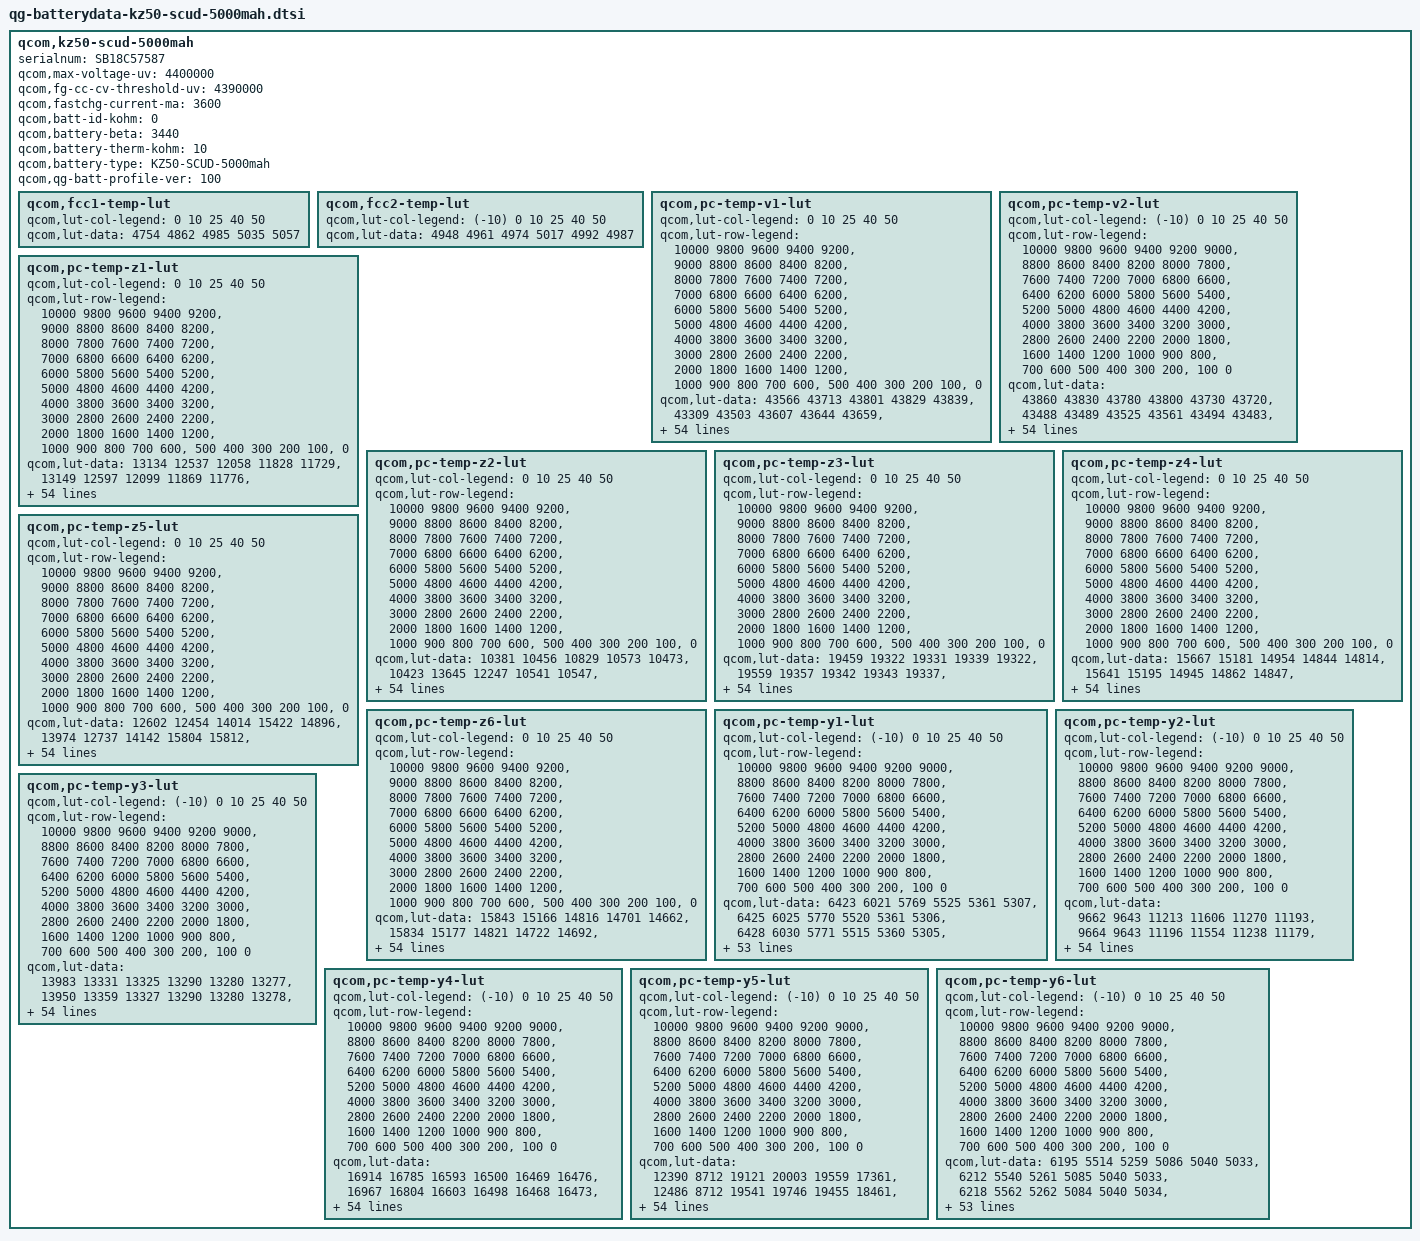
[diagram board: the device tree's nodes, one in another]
qcom,kz50-scud-5000mah {
    /* 4166775_Lenovo_Sofia_SCUD_5000mAH_PMI632_averaged_MasterSlave_Aug21th2019 */
    serialnum = "SB18C57587";
    qcom,max-voltage-uv = <4400000>;
    qcom,fg-cc-cv-threshold-uv = <4390000>;
    qcom,fastchg-current-ma = <3600>;
    qcom,batt-id-kohm = <0>;
    qcom,battery-beta = <3440>;
    qcom,battery-therm-kohm = <10>;
    qcom,battery-type = "KZ50-SCUD-5000mah";
    qcom,qg-batt-profile-ver = <100>;

	qcom,fcc1-temp-lut {
		qcom,lut-col-legend = <0 10 25 40 50>;
		qcom,lut-data = <4754 4862 4985 5035 5057>;
	};

	qcom,fcc2-temp-lut {
		qcom,lut-col-legend = <(-10) 0 10 25 40 50>;
		qcom,lut-data = <4948 4961 4974 5017 4992 4987>;
	};

	qcom,pc-temp-v1-lut {
		qcom,lut-col-legend = <0 10 25 40 50>;
		qcom,lut-row-legend = <10000 9800 9600 9400 9200>,
			<9000 8800 8600 8400 8200>,
			<8000 7800 7600 7400 7200>,
			<7000 6800 6600 6400 6200>,
			<6000 5800 5600 5400 5200>,
			<5000 4800 4600 4400 4200>,
			<4000 3800 3600 3400 3200>,
			<3000 2800 2600 2400 2200>,
			<2000 1800 1600 1400 1200>,
			<1000 900 800 700 600>,
			<500 400 300 200 100>,
			<0>;
		qcom,lut-data = <43566 43713 43801 43829 43839>,
			<43309 43503 43607 43644 43659>,
			<43060 43264 43399 43435 43457>,
			<42821 43005 43174 43218 43244>,
			<42591 42759 42929 42996 43021>,
			<42370 42527 42684 42768 42789>,
			<42156 42302 42446 42533 42557>,
			<41949 42083 42211 42292 42323>,
			<41748 41870 41983 42056 42091>,
			<41549 41661 41760 41827 41863>,
			<41356 41454 41543 41603 41637>,
			<41168 41254 41330 41384 41415>,
			<40995 41070 41122 41167 41194>,
			<40803 40905 40929 40960 40981>,
			<40532 40718 40750 40761 40773>,
			<40198 40439 40556 40568 40572>,
			<39956 40126 40322 40375 40381>,
			<39817 39929 40085 40183 40200>,
			<39706 39816 39908 40000 40021>,
			<39591 39706 39776 39833 39849>,
			<39476 39556 39616 39658 39672>,
			<39361 39381 39341 39422 39449>,
			<39241 39194 39046 39144 39182>,
			<39119 38967 38886 38953 38982>,
			<38991 38765 38789 38837 38862>,
			<38848 38655 38702 38740 38761>,
			<38713 38582 38611 38639 38649>,
			<38607 38517 38526 38543 38535>,
			<38517 38457 38448 38450 38434>,
			<38447 38402 38374 38357 38345>,
			<38398 38352 38306 38272 38266>,
			<38359 38305 38242 38201 38195>,
			<38325 38262 38184 38137 38132>,
			<38296 38224 38131 38076 38067>,
			<38268 38190 38084 38020 38001>,
			<38234 38152 38038 37965 37934>,
			<38195 38114 37993 37912 37871>,
			<38147 38069 37945 37859 37809>,
			<38078 37998 37878 37788 37730>,
			<37993 37900 37783 37689 37625>,
			<37898 37791 37675 37576 37508>,
			<37785 37665 37557 37459 37383>,
			<37650 37526 37424 37329 37249>,
			<37486 37368 37271 37178 37096>,
			<37345 37241 37144 37055 36985>,
			<37248 37162 37071 36984 36923>,
			<37212 37144 37045 36957 36896>,
			<37185 37120 37033 36941 36879>,
			<37151 37091 37004 36909 36841>,
			<37049 36990 36890 36777 36673>,
			<36737 36667 36552 36422 36324>,
			<36274 36205 36091 35958 35860>,
			<35685 35614 35498 35361 35261>,
			<34884 34808 34692 34547 34441>,
			<33604 33529 33413 33255 33140>,
			<30000 30000 30000 30000 30000>;
	};

	qcom,pc-temp-v2-lut {
		qcom,lut-col-legend = <(-10) 0 10 25 40 50>;
		qcom,lut-row-legend = <10000 9800 9600 9400 9200 9000>,
			<8800 8600 8400 8200 8000 7800>,
			<7600 7400 7200 7000 6800 6600>,
			<6400 6200 6000 5800 5600 5400>,
			<5200 5000 4800 4600 4400 4200>,
			<4000 3800 3600 3400 3200 3000>,
			<2800 2600 2400 2200 2000 1800>,
			<1600 1400 1200 1000 900 800>,
			<700 600 500 400 300 200>,
			<100 0>;
		qcom,lut-data = <43860 43830 43780 43800 43730 43720>,
			<43488 43489 43525 43561 43494 43483>,
			<43138 43181 43274 43324 43260 43248>,
			<42814 42912 43027 43086 43025 43014>,
			<42512 42679 42784 42849 42791 42783>,
			<42232 42450 42543 42612 42557 42551>,
			<41966 42209 42304 42377 42323 42318>,
			<41720 41964 42069 42143 42091 42085>,
			<41506 41706 41843 41914 41862 41856>,
			<41304 41415 41626 41688 41636 41630>,
			<41156 41187 41415 41464 41412 41406>,
			<41088 41076 41212 41241 41192 41187>,
			<41041 40994 41014 41023 40975 40970>,
			<40888 40837 40817 40831 40769 40763>,
			<40268 40508 40627 40663 40570 40561>,
			<39669 40156 40412 40475 40377 40366>,
			<39455 39880 40113 40219 40185 40177>,
			<39316 39628 39777 39948 39996 39995>,
			<39160 39415 39541 39742 39808 39811>,
			<38975 39238 39381 39578 39624 39630>,
			<38795 39069 39231 39406 39429 39439>,
			<38634 38879 39060 39188 39199 39209>,
			<38486 38685 38889 38969 38963 38970>,
			<38374 38523 38738 38801 38789 38791>,
			<38292 38383 38605 38665 38655 38656>,
			<38224 38268 38484 38544 38537 38537>,
			<38164 38181 38374 38435 38426 38425>,
			<38111 38112 38273 38336 38325 38322>,
			<38061 38054 38181 38243 38234 38230>,
			<38016 38005 38093 38156 38151 38146>,
			<37972 37962 38014 38077 38076 38069>,
			<37926 37919 37937 38005 38007 38000>,
			<37879 37879 37867 37937 37943 37935>,
			<37829 37838 37814 37869 37870 37858>,
			<37776 37796 37778 37802 37789 37767>,
			<37720 37750 37740 37733 37701 37668>,
			<37658 37697 37686 37660 37604 37559>,
			<37593 37636 37621 37584 37501 37446>,
			<37522 37566 37553 37509 37412 37350>,
			<37442 37488 37486 37436 37338 37272>,
			<37357 37400 37410 37352 37257 37190>,
			<37275 37301 37308 37246 37148 37083>,
			<37194 37191 37187 37129 37030 36967>,
			<37116 37085 37076 36998 36917 36856>,
			<37038 36983 36974 36919 36841 36784>,
			<36944 36886 36907 36880 36809 36752>,
			<36891 36832 36888 36864 36794 36737>,
			<36822 36773 36853 36837 36770 36711>,
			<36731 36691 36777 36775 36712 36641>,
			<36593 36535 36601 36583 36478 36390>,
			<36326 36250 36232 36165 36061 35968>,
			<35912 35805 35688 35620 35522 35420>,
			<35311 35170 34983 34901 34805 34704>,
			<34445 34245 33955 33853 33785 33694>,
			<32973 32770 32489 32484 32409 32235>,
			<29704 27720 27389 27346 27270 27172>;
	};

	qcom,pc-temp-z1-lut {
		qcom,lut-col-legend = <0 10 25 40 50>;
		qcom,lut-row-legend = <10000 9800 9600 9400 9200>,
			<9000 8800 8600 8400 8200>,
			<8000 7800 7600 7400 7200>,
			<7000 6800 6600 6400 6200>,
			<6000 5800 5600 5400 5200>,
			<5000 4800 4600 4400 4200>,
			<4000 3800 3600 3400 3200>,
			<3000 2800 2600 2400 2200>,
			<2000 1800 1600 1400 1200>,
			<1000 900 800 700 600>,
			<500 400 300 200 100>,
			<0>;
		qcom,lut-data = <13134 12537 12058 11828 11729>,
			<13149 12597 12099 11869 11776>,
			<13159 12593 12124 11881 11788>,
			<13160 12579 12126 11884 11794>,
			<13157 12572 12123 11883 11797>,
			<13156 12570 12120 11882 11799>,
			<13157 12570 12117 11883 11802>,
			<13163 12573 12115 11884 11806>,
			<13166 12584 12113 11886 11810>,
			<13150 12589 12111 11889 11817>,
			<13126 12585 12111 11892 11824>,
			<13116 12579 12119 11898 11830>,
			<13107 12573 12129 11906 11836>,
			<13100 12561 12127 11908 11839>,
			<13087 12548 12114 11906 11840>,
			<13061 12534 12106 11904 11841>,
			<13051 12521 12104 11904 11843>,
			<13043 12519 12103 11905 11845>,
			<13032 12527 12104 11906 11847>,
			<13030 12536 12112 11907 11847>,
			<13037 12543 12118 11909 11848>,
			<13043 12548 12119 11910 11849>,
			<13045 12552 12119 11910 11850>,
			<13048 12554 12121 11911 11852>,
			<13051 12557 12124 11914 11853>,
			<13055 12559 12128 11917 11855>,
			<13059 12562 12133 11920 11857>,
			<13061 12565 12139 11923 11860>,
			<13063 12572 12141 11926 11863>,
			<13066 12579 12144 11930 11866>,
			<13073 12582 12146 11934 11869>,
			<13084 12583 12150 11938 11873>,
			<13093 12585 12155 11942 11877>,
			<13106 12593 12158 11946 11881>,
			<13116 12604 12162 11951 11885>,
			<13117 12609 12165 11955 11890>,
			<13111 12611 12171 11958 11894>,
			<13110 12613 12178 11962 11897>,
			<13118 12616 12184 11966 11900>,
			<13128 12622 12189 11971 11904>,
			<13138 12629 12193 11975 11908>,
			<13150 12642 12195 11979 11910>,
			<13161 12651 12198 11983 11913>,
			<13171 12657 12203 11987 11916>,
			<13181 12663 12212 11993 11920>,
			<13199 12675 12222 11998 11921>,
			<13179 12670 12215 11997 11921>,
			<13193 12656 12215 12000 11923>,
			<13207 12665 12220 12003 11928>,
			<13199 12674 12223 12010 11933>,
			<13210 12684 12235 12015 11938>,
			<13241 12693 12250 12024 11947>,
			<13233 12720 12254 12037 11958>,
			<13266 12761 12278 12054 11974>,
			<13266 12761 12278 12054 11974>,
			<13266 12761 12278 12054 11974>;
	};

	qcom,pc-temp-z2-lut {
		qcom,lut-col-legend = <0 10 25 40 50>;
		qcom,lut-row-legend = <10000 9800 9600 9400 9200>,
			<9000 8800 8600 8400 8200>,
			<8000 7800 7600 7400 7200>,
			<7000 6800 6600 6400 6200>,
			<6000 5800 5600 5400 5200>,
			<5000 4800 4600 4400 4200>,
			<4000 3800 3600 3400 3200>,
			<3000 2800 2600 2400 2200>,
			<2000 1800 1600 1400 1200>,
			<1000 900 800 700 600>,
			<500 400 300 200 100>,
			<0>;
		qcom,lut-data = <10381 10456 10829 10573 10473>,
			<10423 13645 12247 10541 10547>,
			<10449 13062 12988 10598 10607>,
			<10454 11329 12852 10710 10637>,
			<10440 10617 12007 11466 10614>,
			<10423 10583 11396 12318 10568>,
			<10416 10563 11038 12114 10549>,
			<10410 10540 10722 11097 10542>,
			<10407 10519 10652 10590 10534>,
			<10458 10502 10627 10556 10510>,
			<10550 10484 10613 10537 10481>,
			<10566 10471 10605 10524 10479>,
			<10468 10509 10599 10513 10497>,
			<10358 10709 10690 10541 10511>,
			<10304 10845 11102 11324 10517>,
			<10255 10734 11454 12241 10520>,
			<10237 10540 11657 12497 10501>,
			<10239 10491 11793 12632 10423>,
			<10243 10506 11659 12608 10382>,
			<10249 10529 11014 11565 10476>,
			<10265 10558 10643 10519 10598>,
			<10281 10593 10716 10517 10620>,
			<10292 10604 10817 10665 10624>,
			<10302 10599 10807 10711 10619>,
			<10315 10593 10695 10604 10592>,
			<10333 10596 10630 10504 10564>,
			<10351 10607 10662 10535 10672>,
			<10366 10612 10714 10625 10997>,
			<10379 10612 10734 10685 11123>,
			<10389 10611 10744 10789 10951>,
			<10394 10611 10751 10870 10725>,
			<10398 10616 10761 10829 10599>,
			<10403 10621 10769 10723 10502>,
			<10409 10626 10770 10653 10432>,
			<10416 10635 10764 10602 10371>,
			<10428 10642 10760 10575 10337>,
			<10444 10649 10781 10581 10366>,
			<10462 10658 10820 10601 10450>,
			<10485 10676 10849 10628 10527>,
			<10504 10698 10875 10705 10598>,
			<10419 10706 10895 10782 10668>,
			<10012 10700 10913 10829 10748>,
			<9901 10697 10923 10856 10826>,
			<10024 10709 10912 10815 10876>,
			<10390 10849 10939 10761 10791>,
			<10531 10886 10934 10669 10553>,
			<10601 10881 10906 10664 10556>,
			<10581 10960 10825 10679 10585>,
			<10841 11121 10872 10754 10677>,
			<10695 11097 11005 10769 10647>,
			<10218 10967 10981 10610 10408>,
			<9983 10854 10904 10464 10285>,
			<9796 10723 10810 10382 10224>,
			<9654 10517 10710 10334 10158>,
			<9654 10517 10710 10334 10158>,
			<9654 10517 10710 10334 10158>;
	};

	qcom,pc-temp-z3-lut {
		qcom,lut-col-legend = <0 10 25 40 50>;
		qcom,lut-row-legend = <10000 9800 9600 9400 9200>,
			<9000 8800 8600 8400 8200>,
			<8000 7800 7600 7400 7200>,
			<7000 6800 6600 6400 6200>,
			<6000 5800 5600 5400 5200>,
			<5000 4800 4600 4400 4200>,
			<4000 3800 3600 3400 3200>,
			<3000 2800 2600 2400 2200>,
			<2000 1800 1600 1400 1200>,
			<1000 900 800 700 600>,
			<500 400 300 200 100>,
			<0>;
		qcom,lut-data = <19459 19322 19331 19339 19322>,
			<19559 19357 19342 19343 19337>,
			<19634 19416 19358 19363 19356>,
			<19664 19498 19379 19381 19374>,
			<19674 19531 19410 19395 19383>,
			<19680 19535 19427 19405 19390>,
			<19680 19537 19431 19407 19396>,
			<19676 19538 19434 19407 19401>,
			<19674 19538 19434 19407 19403>,
			<19680 19538 19433 19407 19402>,
			<19689 19536 19431 19405 19401>,
			<19687 19532 19429 19401 19399>,
			<19656 19531 19427 19393 19395>,
			<19628 19530 19427 19390 19391>,
			<19644 19529 19432 19399 19387>,
			<19690 19525 19435 19408 19383>,
			<19710 19518 19436 19407 19377>,
			<19691 19508 19437 19401 19368>,
			<19661 19491 19433 19393 19362>,
			<19643 19479 19412 19375 19360>,
			<19629 19483 19400 19360 19359>,
			<19622 19493 19404 19360 19357>,
			<19622 19498 19410 19364 19354>,
			<19622 19499 19408 19364 19350>,
			<19624 19500 19394 19350 19339>,
			<19633 19499 19386 19338 19329>,
			<19642 19498 19385 19339 19345>,
			<19642 19496 19384 19347 19395>,
			<19639 19495 19385 19358 19415>,
			<19635 19493 19390 19381 19411>,
			<19629 19492 19395 19398 19403>,
			<19621 19492 19402 19397 19395>,
			<19612 19491 19407 19392 19384>,
			<19601 19490 19408 19387 19374>,
			<19590 19488 19407 19379 19365>,
			<19581 19485 19404 19371 19357>,
			<19573 19482 19400 19364 19352>,
			<19566 19478 19395 19358 19347>,
			<19560 19474 19392 19355 19345>,
			<19553 19470 19389 19353 19344>,
			<19504 19467 19387 19352 19344>,
			<19323 19463 19386 19354 19350>,
			<19266 19459 19384 19357 19360>,
			<19264 19453 19380 19356 19362>,
			<19261 19427 19372 19352 19358>,
			<19260 19403 19359 19339 19338>,
			<19260 19338 19361 19338 19335>,
			<19260 19322 19341 19330 19326>,
			<19259 19305 19340 19324 19318>,
			<19259 19316 19328 19331 19335>,
			<19261 19320 19352 19356 19353>,
			<19263 19317 19361 19359 19355>,
			<19265 19314 19366 19360 19355>,
			<19268 19311 19338 19352 19351>,
			<19268 19311 19338 19352 19351>,
			<19268 19311 19338 19352 19351>;
	};

	qcom,pc-temp-z4-lut {
		qcom,lut-col-legend = <0 10 25 40 50>;
		qcom,lut-row-legend = <10000 9800 9600 9400 9200>,
			<9000 8800 8600 8400 8200>,
			<8000 7800 7600 7400 7200>,
			<7000 6800 6600 6400 6200>,
			<6000 5800 5600 5400 5200>,
			<5000 4800 4600 4400 4200>,
			<4000 3800 3600 3400 3200>,
			<3000 2800 2600 2400 2200>,
			<2000 1800 1600 1400 1200>,
			<1000 900 800 700 600>,
			<500 400 300 200 100>,
			<0>;
		qcom,lut-data = <15667 15181 14954 14844 14814>,
			<15641 15195 14945 14862 14847>,
			<15591 15169 14929 14861 14844>,
			<15525 15092 14906 14858 14841>,
			<15414 15022 14869 14821 14828>,
			<15294 14962 14837 14776 14807>,
			<15207 14908 14815 14765 14788>,
			<15136 14864 14795 14761 14771>,
			<15073 14826 14776 14756 14755>,
			<15010 14800 14757 14742 14740>,
			<14953 14785 14742 14726 14727>,
			<14920 14772 14732 14718 14716>,
			<14900 14747 14723 14712 14708>,
			<14884 14698 14703 14702 14701>,
			<14872 14669 14664 14671 14697>,
			<14862 14694 14644 14644 14695>,
			<14849 14737 14648 14642 14692>,
			<14826 14745 14654 14642 14690>,
			<14799 14721 14659 14643 14688>,
			<14779 14701 14664 14657 14689>,
			<14763 14701 14672 14682 14690>,
			<14750 14705 14736 14729 14713>,
			<14739 14715 14818 14799 14789>,
			<14731 14768 14830 14824 14824>,
			<14729 14821 14828 14825 14824>,
			<14737 14822 14823 14825 14822>,
			<14749 14806 14813 14817 14798>,
			<14756 14790 14797 14794 14732>,
			<14763 14776 14781 14767 14700>,
			<14766 14762 14763 14733 14695>,
			<14762 14749 14746 14705 14692>,
			<14753 14737 14730 14695 14689>,
			<14746 14727 14716 14689 14685>,
			<14739 14717 14707 14688 14684>,
			<14732 14708 14701 14688 14685>,
			<14726 14701 14698 14689 14686>,
			<14720 14694 14696 14689 14685>,
			<14715 14690 14694 14688 14685>,
			<14710 14690 14695 14689 14686>,
			<14706 14691 14700 14700 14699>,
			<14748 14691 14703 14708 14709>,
			<14942 14688 14699 14703 14702>,
			<15000 14684 14692 14695 14692>,
			<14986 14680 14690 14695 14692>,
			<14914 14664 14674 14683 14681>,
			<14903 14667 14657 14666 14665>,
			<14899 14731 14646 14656 14657>,
			<14894 14743 14651 14645 14645>,
			<14884 14755 14641 14632 14630>,
			<14876 14738 14657 14633 14635>,
			<14885 14748 14658 14649 14658>,
			<14899 14759 14653 14654 14665>,
			<14911 14770 14653 14658 14671>,
			<14927 14782 14688 14671 14678>,
			<14927 14782 14688 14671 14678>,
			<14927 14782 14688 14671 14678>;
	};

	qcom,pc-temp-z5-lut {
		qcom,lut-col-legend = <0 10 25 40 50>;
		qcom,lut-row-legend = <10000 9800 9600 9400 9200>,
			<9000 8800 8600 8400 8200>,
			<8000 7800 7600 7400 7200>,
			<7000 6800 6600 6400 6200>,
			<6000 5800 5600 5400 5200>,
			<5000 4800 4600 4400 4200>,
			<4000 3800 3600 3400 3200>,
			<3000 2800 2600 2400 2200>,
			<2000 1800 1600 1400 1200>,
			<1000 900 800 700 600>,
			<500 400 300 200 100>,
			<0>;
		qcom,lut-data = <12602 12454 14014 15422 14896>,
			<13974 12737 14142 15804 15812>,
			<15064 14290 14472 17410 17523>,
			<15719 17127 15265 18726 19191>,
			<16095 18981 17207 19362 20117>,
			<16377 19795 18914 19935 20889>,
			<16661 20500 20106 20847 21904>,
			<16977 21542 21183 22100 23253>,
			<17384 22853 22060 23219 24518>,
			<18235 24128 22847 24287 25483>,
			<19173 25214 23680 25043 26381>,
			<19271 26331 24495 25153 27434>,
			<18342 27957 25515 25167 28723>,
			<17522 30493 27949 25533 29796>,
			<19366 31934 33103 32966 30652>,
			<24263 31411 35835 40853 31262>,
			<26510 30258 35687 41396 30995>,
			<25232 29195 35417 41187 29574>,
			<23579 27999 35470 40532 28838>,
			<23351 27248 35705 34753 30328>,
			<23841 33976 36145 29058 32198>,
			<24677 49538 40084 28701 31609>,
			<26582 55290 45187 28814 28248>,
			<30279 54201 43571 28386 24568>,
			<35260 52229 32694 23089 20121>,
			<45263 49073 25103 18040 16691>,
			<54223 43871 23338 17670 19365>,
			<55479 40253 22341 17754 28232>,
			<55044 38356 22362 18456 32395>,
			<54120 37158 23228 23391 32970>,
			<51607 37211 24580 28771 33232>,
			<47568 38376 27518 31375 32568>,
			<43595 39924 31678 33251 30774>,
			<39074 41972 35423 33804 29943>,
			<35352 44332 39382 33931 29768>,
			<33502 45804 41253 33982 29657>,
			<32216 46872 41112 33343 29573>,
			<31470 47431 40759 31914 29498>,
			<31158 47268 40096 30912 29195>,
			<30843 46682 38490 29503 27480>,
			<27657 45729 36681 28305 26100>,
			<15276 43016 35020 27651 27683>,
			<11503 40192 33330 27244 30833>,
			<11534 37967 31301 27338 33088>,
			<11741 35387 32446 27693 32626>,
			<11713 29246 28988 23755 23354>,
			<11690 14788 31741 24748 23129>,
			<11661 13834 22179 23574 22747>,
			<11635 13105 23518 25736 25810>,
			<11711 13847 19170 27610 44543>,
			<11788 13994 22978 28421 27463>,
			<11685 13552 24272 25977 23446>,
			<11583 13156 24489 23205 20425>,
			<11472 12797 16276 18119 16947>,
			<11472 12797 16276 18119 16947>,
			<11472 12797 16276 18119 16947>;
	};

	qcom,pc-temp-z6-lut {
		qcom,lut-col-legend = <0 10 25 40 50>;
		qcom,lut-row-legend = <10000 9800 9600 9400 9200>,
			<9000 8800 8600 8400 8200>,
			<8000 7800 7600 7400 7200>,
			<7000 6800 6600 6400 6200>,
			<6000 5800 5600 5400 5200>,
			<5000 4800 4600 4400 4200>,
			<4000 3800 3600 3400 3200>,
			<3000 2800 2600 2400 2200>,
			<2000 1800 1600 1400 1200>,
			<1000 900 800 700 600>,
			<500 400 300 200 100>,
			<0>;
		qcom,lut-data = <15843 15166 14816 14701 14662>,
			<15834 15177 14821 14722 14692>,
			<15809 15170 14823 14734 14705>,
			<15774 15159 14822 14737 14712>,
			<15705 15143 14817 14730 14711>,
			<15624 15109 14811 14719 14707>,
			<15564 15070 14802 14715 14704>,
			<15512 15042 14791 14712 14700>,
			<15469 15019 14781 14709 14695>,
			<15435 15000 14771 14704 14690>,
			<15405 14987 14763 14698 14686>,
			<15369 14975 14759 14692 14681>,
			<15320 14956 14754 14687 14676>,
			<15285 14924 14745 14681 14671>,
			<15279 14906 14728 14674 14667>,
			<15277 14910 14720 14668 14663>,
			<15273 14917 14723 14665 14659>,
			<15249 14916 14726 14662 14653>,
			<15217 14900 14725 14660 14650>,
			<15197 14886 14717 14658 14649>,
			<15181 14888 14712 14657 14648>,
			<15172 14896 14742 14671 14657>,
			<15170 14908 14782 14706 14687>,
			<15170 14934 14787 14718 14702>,
			<15170 14957 14781 14713 14697>,
			<15180 14958 14774 14707 14691>,
			<15193 14952 14768 14702 14689>,
			<15199 14945 14763 14698 14688>,
			<15202 14940 14759 14694 14686>,
			<15203 14934 14755 14692 14682>,
			<15201 14930 14751 14690 14677>,
			<15195 14926 14749 14686 14672>,
			<15189 14923 14746 14682 14666>,
			<15184 14920 14744 14678 14660>,
			<15179 14918 14742 14675 14657>,
			<15176 14916 14741 14673 14653>,
			<15173 14914 14739 14669 14650>,
			<15172 14913 14737 14665 14647>,
			<15173 14914 14737 14665 14647>,
			<15176 14918 14739 14669 14651>,
			<15177 14920 14741 14672 14656>,
			<15178 14921 14740 14672 14658>,
			<15181 14922 14738 14671 14659>,
			<15188 14923 14737 14671 14660>,
			<15174 14914 14730 14665 14654>,
			<15173 14906 14718 14651 14636>,
			<15172 14901 14714 14646 14632>,
			<15170 14899 14706 14637 14622>,
			<15170 14898 14703 14629 14611>,
			<15175 14902 14706 14634 14623>,
			<15187 14914 14722 14656 14645>,
			<15203 14923 14728 14663 14652>,
			<15221 14935 14735 14668 14657>,
			<15248 14953 14742 14674 14662>,
			<15248 14953 14742 14674 14662>,
			<15248 14953 14742 14674 14662>;
	};

	qcom,pc-temp-y1-lut {
		qcom,lut-col-legend = <(-10) 0 10 25 40 50>;
		qcom,lut-row-legend = <10000 9800 9600 9400 9200 9000>,
			<8800 8600 8400 8200 8000 7800>,
			<7600 7400 7200 7000 6800 6600>,
			<6400 6200 6000 5800 5600 5400>,
			<5200 5000 4800 4600 4400 4200>,
			<4000 3800 3600 3400 3200 3000>,
			<2800 2600 2400 2200 2000 1800>,
			<1600 1400 1200 1000 900 800>,
			<700 600 500 400 300 200>,
			<100 0>;
		qcom,lut-data = <6423 6021 5769 5525 5361 5307>,
			<6425 6025 5770 5520 5361 5306>,
			<6428 6030 5771 5515 5360 5305>,
			<6430 6035 5771 5511 5359 5304>,
			<6433 6039 5771 5506 5357 5304>,
			<6436 6042 5772 5502 5356 5303>,
			<6439 6043 5773 5499 5354 5302>,
			<6442 6043 5774 5496 5351 5301>,
			<6443 6044 5772 5493 5350 5301>,
			<6440 6044 5766 5490 5349 5300>,
			<6438 6044 5760 5487 5348 5300>,
			<6447 6044 5758 5486 5347 5299>,
			<6464 6042 5757 5485 5347 5298>,
			<6467 6044 5756 5483 5346 5298>,
			<6455 6051 5756 5480 5344 5298>,
			<6444 6057 5755 5478 5343 5298>,
			<6446 6061 5759 5481 5344 5298>,
			<6454 6066 5767 5486 5345 5298>,
			<6455 6068 5770 5487 5346 5299>,
			<6450 6069 5771 5484 5345 5299>,
			<6446 6070 5771 5483 5345 5300>,
			<6440 6070 5770 5484 5345 5301>,
			<6433 6069 5769 5486 5347 5302>,
			<6430 6068 5768 5487 5348 5303>,
			<6435 6063 5767 5489 5349 5305>,
			<6441 6059 5767 5490 5350 5306>,
			<6446 6063 5767 5492 5352 5308>,
			<6452 6072 5767 5494 5354 5310>,
			<6453 6074 5768 5497 5357 5312>,
			<6446 6064 5769 5499 5359 5313>,
			<6438 6056 5771 5501 5362 5315>,
			<6438 6057 5772 5503 5364 5317>,
			<6441 6061 5773 5506 5367 5320>,
			<6441 6062 5774 5508 5369 5321>,
			<6437 6061 5773 5510 5371 5323>,
			<6433 6061 5773 5512 5373 5324>,
			<6435 6063 5774 5514 5376 5326>,
			<6444 6068 5774 5515 5378 5329>,
			<6449 6071 5773 5516 5380 5331>,
			<6445 6072 5772 5517 5382 5333>,
			<6437 6073 5771 5519 5383 5335>,
			<6427 6075 5774 5522 5386 5336>,
			<6418 6078 5779 5527 5389 5337>,
			<6428 6072 5780 5531 5395 5342>,
			<6450 6065 5781 5538 5399 5346>,
			<6447 6082 5788 5542 5399 5345>,
			<6472 6096 5792 5539 5398 5344>,
			<6497 6096 5794 5538 5398 5345>,
			<6501 6096 5795 5542 5398 5346>,
			<6469 6107 5793 5539 5400 5348>,
			<6487 6110 5805 5542 5405 5351>,
			<6512 6133 5818 5556 5412 5358>,
			<6521 6142 5832 5571 5423 5366>,
			<6535 6164 5852 5587 5436 5378>,
			<6535 6164 5852 5587 5436 5378>,
			<6535 6164 5852 5587 5436 5378>;
	};

	qcom,pc-temp-y2-lut {
		qcom,lut-col-legend = <(-10) 0 10 25 40 50>;
		qcom,lut-row-legend = <10000 9800 9600 9400 9200 9000>,
			<8800 8600 8400 8200 8000 7800>,
			<7600 7400 7200 7000 6800 6600>,
			<6400 6200 6000 5800 5600 5400>,
			<5200 5000 4800 4600 4400 4200>,
			<4000 3800 3600 3400 3200 3000>,
			<2800 2600 2400 2200 2000 1800>,
			<1600 1400 1200 1000 900 800>,
			<700 600 500 400 300 200>,
			<100 0>;
		qcom,lut-data = <9662 9643 11213 11606 11270 11193>,
			<9664 9643 11196 11554 11238 11179>,
			<9665 9658 11179 11494 11207 11156>,
			<9666 10093 11163 11436 11177 11126>,
			<9668 10463 11149 11386 11149 11094>,
			<9669 10626 11139 11352 11122 11060>,
			<9670 10623 11130 11331 11095 11003>,
			<9671 10615 11123 11315 11070 10942>,
			<9671 10612 11124 11307 11054 10934>,
			<9669 10611 11141 11300 11044 10957>,
			<9668 10613 11152 11294 11034 10972>,
			<9668 10630 11128 11287 11017 10964>,
			<9668 10661 11086 11279 10998 10949>,
			<9668 10698 11110 11273 10998 10945>,
			<9667 10745 11332 11267 11022 10946>,
			<9667 10803 11495 11265 11058 10950>,
			<9667 10891 11437 11363 11122 10971>,
			<9666 10992 11330 11517 11219 11017>,
			<9666 11036 11309 11592 11331 11097>,
			<9666 11055 11347 11646 11484 11289>,
			<9666 11064 11380 11666 11567 11414>,
			<9666 10736 11384 11630 11489 11363>,
			<9666 10025 11384 11581 11362 11274>,
			<9665 9770 11393 11575 11342 11249>,
			<9665 9743 11430 11582 11388 11248>,
			<9664 9729 11467 11593 11426 11251>,
			<9664 9723 11485 11627 11439 11287>,
			<9664 9719 11498 11671 11451 11359>,
			<9664 9715 11502 11691 11468 11426>,
			<9663 9709 11500 11706 11510 11504>,
			<9663 9703 11498 11717 11561 11567>,
			<9663 9697 11365 11735 11642 11607>,
			<9662 9691 11088 11753 11732 11641>,
			<9662 9686 11027 11736 11740 11664>,
			<9662 9682 11249 11667 11672 11683>,
			<9662 9678 11430 11632 11596 11685>,
			<9661 9674 11081 11644 11530 11605>,
			<9661 9671 10331 11659 11473 11457>,
			<9661 9669 10136 11650 11465 11374>,
			<9661 9667 10657 11606 11484 11326>,
			<9661 9665 11130 11568 11497 11295>,
			<9661 9663 11101 11546 11465 11296>,
			<9661 9662 10975 11516 11395 11299>,
			<9661 9661 10869 11422 11291 11189>,
			<9660 9660 10560 11393 11192 11031>,
			<9660 9660 10209 11376 11209 11016>,
			<9660 9660 10586 11382 11199 11069>,
			<9660 9660 10654 11391 11260 11064>,
			<9660 9660 10645 11410 11278 11057>,
			<9660 9660 10631 11379 11206 10943>,
			<9659 9659 10171 11290 11060 10882>,
			<9659 9659 9750 11193 11020 10799>,
			<9659 9658 9707 11082 10899 10695>,
			<9658 9657 9690 10984 10720 10493>,
			<9658 9657 9690 10984 10720 10493>,
			<9658 9657 9690 10984 10720 10493>;
	};

	qcom,pc-temp-y3-lut {
		qcom,lut-col-legend = <(-10) 0 10 25 40 50>;
		qcom,lut-row-legend = <10000 9800 9600 9400 9200 9000>,
			<8800 8600 8400 8200 8000 7800>,
			<7600 7400 7200 7000 6800 6600>,
			<6400 6200 6000 5800 5600 5400>,
			<5200 5000 4800 4600 4400 4200>,
			<4000 3800 3600 3400 3200 3000>,
			<2800 2600 2400 2200 2000 1800>,
			<1600 1400 1200 1000 900 800>,
			<700 600 500 400 300 200>,
			<100 0>;
		qcom,lut-data = <13983 13331 13325 13290 13280 13277>,
			<13950 13359 13327 13290 13280 13278>,
			<13919 13385 13329 13291 13281 13279>,
			<13890 13406 13331 13292 13282 13281>,
			<13863 13422 13333 13293 13282 13282>,
			<13838 13428 13335 13293 13283 13282>,
			<13818 13422 13335 13294 13283 13283>,
			<13799 13413 13336 13294 13283 13283>,
			<13756 13412 13337 13295 13284 13283>,
			<13639 13418 13339 13296 13285 13284>,
			<13557 13423 13340 13297 13285 13285>,
			<13567 13397 13342 13298 13285 13285>,
			<13588 13350 13344 13300 13285 13285>,
			<13592 13340 13344 13302 13286 13285>,
			<13576 13360 13339 13307 13291 13287>,
			<13562 13376 13332 13309 13293 13289>,
			<13561 13374 13328 13305 13294 13290>,
			<13561 13370 13323 13299 13294 13290>,
			<13562 13366 13320 13297 13294 13291>,
			<13562 13362 13318 13297 13293 13291>,
			<13562 13357 13316 13297 13292 13292>,
			<13562 13351 13314 13294 13287 13287>,
			<13561 13342 13312 13290 13281 13280>,
			<13562 13333 13310 13288 13279 13278>,
			<13577 13320 13309 13287 13280 13278>,
			<13599 13310 13308 13286 13280 13278>,
			<13617 13306 13307 13286 13279 13278>,
			<13636 13302 13307 13287 13278 13277>,
			<13657 13303 13306 13286 13277 13277>,
			<13685 13307 13306 13286 13278 13278>,
			<13716 13315 13306 13286 13278 13278>,
			<13749 13325 13302 13286 13279 13278>,
			<13784 13340 13296 13286 13279 13278>,
			<13822 13357 13295 13286 13280 13278>,
			<13864 13378 13301 13286 13280 13279>,
			<13908 13402 13307 13286 13280 13279>,
			<13953 13430 13303 13286 13279 13278>,
			<14001 13461 13294 13285 13278 13277>,
			<14048 13498 13292 13286 13278 13277>,
			<14094 13546 13302 13287 13280 13279>,
			<14140 13601 13313 13287 13282 13280>,
			<14182 13663 13315 13288 13281 13280>,
			<14222 13735 13317 13288 13280 13280>,
			<14269 13817 13321 13285 13280 13280>,
			<14321 13903 13326 13289 13281 13283>,
			<14366 13949 13329 13292 13289 13287>,
			<14329 13910 13335 13297 13290 13289>,
			<14373 13957 13344 13300 13292 13290>,
			<14426 14003 13351 13302 13293 13289>,
			<14488 14040 13355 13301 13288 13286>,
			<14535 14080 13362 13299 13286 13285>,
			<14608 14153 13380 13302 13291 13287>,
			<14709 14265 13410 13309 13295 13294>,
			<14835 14410 13459 13318 13303 13303>,
			<14835 14410 13459 13318 13303 13303>,
			<14835 14410 13459 13318 13303 13303>;
	};

	qcom,pc-temp-y4-lut {
		qcom,lut-col-legend = <(-10) 0 10 25 40 50>;
		qcom,lut-row-legend = <10000 9800 9600 9400 9200 9000>,
			<8800 8600 8400 8200 8000 7800>,
			<7600 7400 7200 7000 6800 6600>,
			<6400 6200 6000 5800 5600 5400>,
			<5200 5000 4800 4600 4400 4200>,
			<4000 3800 3600 3400 3200 3000>,
			<2800 2600 2400 2200 2000 1800>,
			<1600 1400 1200 1000 900 800>,
			<700 600 500 400 300 200>,
			<100 0>;
		qcom,lut-data = <16914 16785 16593 16500 16469 16476>,
			<16967 16804 16603 16498 16468 16473>,
			<17039 16823 16616 16497 16468 16471>,
			<17111 16841 16630 16496 16468 16469>,
			<17168 16858 16641 16496 16468 16468>,
			<17193 16875 16646 16496 16468 16468>,
			<17185 16893 16645 16497 16469 16468>,
			<17172 16909 16642 16499 16472 16470>,
			<17198 16908 16644 16501 16474 16470>,
			<17415 16880 16657 16506 16477 16472>,
			<17638 16859 16672 16511 16481 16473>,
			<17753 17046 16680 16517 16485 16477>,
			<17838 17386 16689 16523 16491 16481>,
			<17799 17447 16717 16537 16496 16485>,
			<17302 17233 16813 16564 16501 16489>,
			<16884 17003 16880 16588 16507 16493>,
			<16874 16873 16807 16603 16518 16500>,
			<16878 16772 16670 16613 16532 16509>,
			<16875 16737 16625 16614 16547 16523>,
			<16827 16729 16618 16610 16566 16546>,
			<16772 16721 16611 16602 16577 16560>,
			<16742 16701 16588 16557 16545 16534>,
			<16720 16672 16556 16500 16490 16489>,
			<16708 16650 16538 16485 16473 16474>,
			<16700 16631 16529 16480 16469 16470>,
			<16697 16618 16523 16478 16467 16468>,
			<16697 16618 16521 16480 16469 16469>,
			<16700 16620 16520 16485 16475 16472>,
			<16704 16623 16517 16489 16482 16476>,
			<16707 16627 16512 16495 16489 16483>,
			<16711 16631 16508 16500 16498 16491>,
			<16716 16634 16508 16507 16510 16504>,
			<16723 16638 16511 16513 16521 16517>,
			<16730 16642 16512 16512 16522 16520>,
			<16738 16649 16509 16509 16516 16515>,
			<16743 16656 16509 16503 16507 16508>,
			<16744 16665 16525 16490 16490 16493>,
			<16745 16675 16555 16477 16471 16475>,
			<16745 16681 16564 16476 16468 16472>,
			<16744 16684 16555 16478 16475 16481>,
			<16744 16687 16548 16480 16480 16487>,
			<16747 16689 16550 16482 16478 16485>,
			<16762 16691 16557 16483 16472 16479>,
			<16782 16704 16564 16481 16461 16461>,
			<16812 16742 16585 16484 16462 16462>,
			<16844 16785 16615 16499 16496 16512>,
			<16808 16766 16618 16523 16529 16547>,
			<16829 16804 16656 16556 16565 16584>,
			<16852 16850 16705 16582 16586 16592>,
			<16858 16881 16716 16569 16513 16513>,
			<16851 16888 16701 16523 16484 16487>,
			<16829 16881 16699 16526 16485 16488>,
			<16827 16879 16731 16549 16489 16486>,
			<16849 16910 16792 16606 16528 16525>,
			<16849 16910 16792 16606 16528 16525>,
			<16849 16910 16792 16606 16528 16525>;
	};

	qcom,pc-temp-y5-lut {
		qcom,lut-col-legend = <(-10) 0 10 25 40 50>;
		qcom,lut-row-legend = <10000 9800 9600 9400 9200 9000>,
			<8800 8600 8400 8200 8000 7800>,
			<7600 7400 7200 7000 6800 6600>,
			<6400 6200 6000 5800 5600 5400>,
			<5200 5000 4800 4600 4400 4200>,
			<4000 3800 3600 3400 3200 3000>,
			<2800 2600 2400 2200 2000 1800>,
			<1600 1400 1200 1000 900 800>,
			<700 600 500 400 300 200>,
			<100 0>;
		qcom,lut-data = <12390 8712 19121 20003 19559 17361>,
			<12486 8712 19541 19746 19455 18461>,
			<12635 11694 19720 19466 19252 19130>,
			<12827 14731 19716 19190 18972 19475>,
			<13054 16997 19589 18949 18637 19603>,
			<13309 17926 19394 18771 18269 19620>,
			<13675 17597 19057 18393 17730 19112>,
			<14044 16813 18582 17837 17107 18237>,
			<13963 15837 18157 17408 16716 17865>,
			<12854 14279 17772 16887 16448 17613>,
			<12000 13321 17340 16551 16185 17346>,
			<14261 13377 16644 16463 15671 16711>,
			<18632 13582 15930 16400 15106 15923>,
			<19466 14520 15814 16206 15109 15819>,
			<16128 19464 16110 15755 15715 16137>,
			<13327 23288 16633 15512 16123 16357>,
			<13684 22545 18611 15678 15957 16072>,
			<14618 20945 21532 16078 15686 15595>,
			<14928 20582 22244 17166 15948 15700>,
			<14891 21399 22225 20077 17753 17016>,
			<14795 22091 22214 21885 19046 18074>,
			<14163 20455 22289 22238 19032 18278>,
			<12855 16633 22417 22430 18923 18380>,
			<12398 14556 22434 22299 19050 18438>,
			<12477 13590 22311 21677 19545 18709>,
			<12554 13022 22211 21289 19866 18891>,
			<12541 12803 22289 21369 18858 18253>,
			<12494 12623 22514 21488 17191 17138>,
			<12480 12522 22849 21386 16852 16791>,
			<12606 12442 23634 21218 17017 16713>,
			<12781 12392 24213 21152 17287 16681>,
			<12889 12452 22509 21746 17800 16839>,
			<12974 12659 18925 22729 18650 17275>,
			<13059 12907 18133 23544 19805 18020>,
			<13142 13289 21002 24365 21710 19801>,
			<13235 13618 23489 24682 22839 21007>,
			<13380 13706 21094 24283 22253 20943>,
			<13585 13746 15625 23743 21249 20801>,
			<13673 13810 14116 23469 21137 20806>,
			<13552 13987 17046 23007 21845 21129>,
			<13347 14143 19704 22486 22351 21452>,
			<13164 14082 19317 21883 21883 22170>,
			<12989 13869 18369 20882 20928 22940>,
			<13037 13627 18201 17734 19940 21884>,
			<13245 13409 17296 18312 18236 19599>,
			<13374 13561 15481 18373 17988 16746>,
			<13634 14235 17367 18752 17391 16140>,
			<13733 14833 17827 18553 16943 15569>,
			<13986 15827 18129 18666 16910 15309>,
			<14729 16469 18896 18840 17070 16360>,
			<14072 16607 17513 19412 17128 16114>,
			<13692 15967 15187 19495 18384 15526>,
			<13232 14679 14318 19978 19148 18007>,
			<13170 13447 14035 21148 23586 23926>,
			<13170 13447 14035 21148 23586 23926>,
			<13170 13447 14035 21148 23586 23926>;
	};

	qcom,pc-temp-y6-lut {
		qcom,lut-col-legend = <(-10) 0 10 25 40 50>;
		qcom,lut-row-legend = <10000 9800 9600 9400 9200 9000>,
			<8800 8600 8400 8200 8000 7800>,
			<7600 7400 7200 7000 6800 6600>,
			<6400 6200 6000 5800 5600 5400>,
			<5200 5000 4800 4600 4400 4200>,
			<4000 3800 3600 3400 3200 3000>,
			<2800 2600 2400 2200 2000 1800>,
			<1600 1400 1200 1000 900 800>,
			<700 600 500 400 300 200>,
			<100 0>;
		qcom,lut-data = <6195 5514 5259 5086 5040 5033>,
			<6212 5540 5261 5085 5040 5033>,
			<6218 5562 5262 5084 5040 5034>,
			<6216 5578 5261 5083 5041 5034>,
			<6207 5588 5259 5082 5041 5035>,
			<6195 5592 5256 5082 5041 5035>,
			<6173 5588 5251 5082 5042 5036>,
			<6147 5579 5246 5082 5043 5036>,
			<6136 5569 5245 5082 5043 5037>,
			<6132 5553 5246 5083 5045 5038>,
			<6130 5543 5247 5084 5046 5039>,
			<6152 5573 5247 5086 5047 5040>,
			<6194 5628 5248 5088 5049 5041>,
			<6189 5637 5253 5094 5051 5043>,
			<6044 5595 5272 5105 5055 5045>,
			<5922 5547 5286 5111 5059 5047>,
			<5919 5515 5264 5112 5063 5050>,
			<5921 5489 5223 5112 5067 5053>,
			<5920 5477 5208 5112 5071 5057>,
			<5908 5472 5204 5110 5075 5064>,
			<5894 5467 5200 5107 5077 5068>,
			<5888 5454 5192 5092 5065 5057>,
			<5883 5435 5181 5073 5044 5039>,
			<5883 5426 5175 5067 5038 5033>,
			<5892 5422 5173 5065 5037 5032>,
			<5907 5420 5171 5065 5037 5032>,
			<5921 5423 5172 5066 5037 5032>,
			<5936 5433 5172 5068 5038 5033>,
			<5954 5444 5173 5069 5040 5034>,
			<5975 5457 5174 5071 5043 5036>,
			<5998 5472 5174 5073 5046 5039>,
			<6024 5490 5174 5076 5050 5043>,
			<6052 5512 5173 5079 5054 5047>,
			<6082 5536 5174 5079 5054 5048>,
			<6115 5565 5181 5078 5053 5047>,
			<6149 5596 5190 5077 5051 5045>,
			<6184 5631 5195 5075 5046 5041>,
			<6220 5669 5200 5072 5040 5035>,
			<6256 5711 5207 5072 5039 5034>,
			<6289 5757 5222 5074 5043 5038>,
			<6322 5807 5239 5076 5046 5042>,
			<6358 5861 5255 5078 5045 5041>,
			<6395 5921 5272 5080 5043 5039>,
			<6437 5990 5296 5080 5041 5035>,
			<6485 6068 5328 5087 5043 5037>,
			<6530 6119 5348 5094 5058 5056>,
			<6502 6087 5356 5105 5069 5067>,
			<6543 6133 5384 5117 5080 5078>,
			<6591 6182 5410 5126 5087 5080>,
			<6642 6221 5425 5121 5063 5055>,
			<6681 6259 5429 5108 5054 5048>,
			<6737 6316 5451 5117 5059 5050>,
			<6822 6408 5516 5132 5064 5056>,
			<6936 6536 5598 5162 5084 5076>,
			<6936 6536 5598 5162 5084 5076>,
			<6936 6536 5598 5162 5084 5076>;
	};

};
